# STM32F373C8T6 register map
File version: 1.0
STM32F373C8T6,STM32F373CBT6,STM32F373CBT7,STM32F373CCT6,STM32F373CCT7,STM32F373R8T6,STM32F373RBT6,STM32F373RBT7,STM32F373RCT6,STM32F373V8H6,STM32F373V8T6,STM32F373VBH6,STM32F373VBH7,STM32F373VBT6,STM32F373VBT7,STM32F373VCH6,STM32F373VCH7,STM32F373VCT6,STM32F373VCT7,STM32F378CCT6,STM32F378RCT6,STM32F378RCY6,STM32F378VCH6,STM32F378VCT6
Registers are 32-bit, access not given, reset 0x0 unless marked. A register's access mark holds for its fields unless they carry their own. Offsets are from the block's base; lines under a group give offsets from that group; [hi:lo] are bit positions; {n}, {i} and the like mark numbered series; 'fields as' and 'values as' point back to an identical list; <NAME> marks a mode.

## Memory map
0x40000000 TIM2
0x40000400 TIM3
0x40000800 TIM4
0x40000C00 TIM5
0x40001000 TIM6
0x40001400 TIM7
0x40001800 TIM12
0x40001C00 TIM13
0x40002000 TIM14
0x40002800 RTC
0x40002C00 WWDG
0x40003000 IWDG
0x40003800 SPI2
0x40003C00 SPI3
0x40004400 USART2
0x40004800 USART3
0x40005400 I2C1
0x40005800 I2C2
0x40005C00 USBFS
0x40006000 USB
0x40006400 CAN
0x40007000 PWR
0x40007400 DAC1
0x40007800 CEC
0x40009800 DAC2
0x40009C00 TIM18
0x40010000 COMP
0x40010000 SYSCFG
0x40010400 EXTI
0x40012400 ADC
0x40013000 SPI1
0x40013800 USART1
0x40014000 TIM15
0x40014400 TIM16
0x40014800 TIM17
0x40015800 DBGMCU
0x40015C00 TIM19
0x40016000 SDADC1
0x40016400 SDADC2
0x40016800 SDADC3
0x40020000 DMA1
0x40020400 DMA2
0x40021000 RCC
0x40022000 FLASH
0x40023000 CRC
0x40024000 TSC
0x48000000 GPIOA
0x48000400 GPIOB
0x48000800 GPIOC
0x48000C00 GPIOD
0x48001000 GPIOE
0x48001400 GPIOF

## TIM2
Base 0x40000000
Same registers: TIM3 0x40000400, TIM4 0x40000800, TIM5 0x40000C00, TIM19 0x40015C00
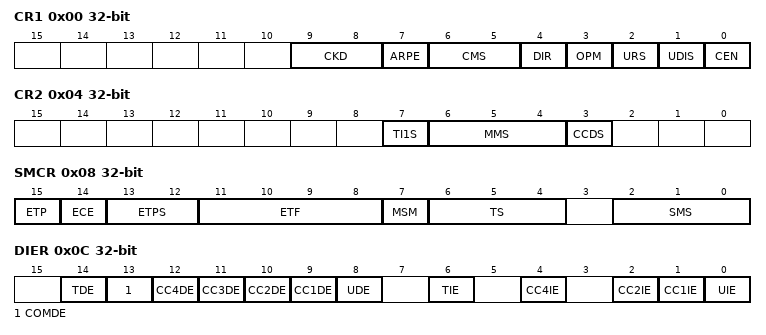
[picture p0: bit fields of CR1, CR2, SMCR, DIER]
0x00 CR1
  [9:8] CKD, [7] ARPE, [6:5] CMS, [4] DIR, [3] OPM, [2] URS, [1] UDIS, [0] CEN
0x04 CR2
  [7] TI1S, [6:4] MMS, [3] CCDS
0x08 SMCR
  [15] ETP, [14] ECE, [13:12] ETPS, [11:8] ETF, [7] MSM, [6:4] TS, [2:0] SMS
0x0C DIER
  [14] TDE, [13] COMDE, [n+8] CC{n}DE (n=1..4), [8] UDE, [6] TIE, [4] CC4IE, [2] CC2IE, [1] CC1IE, [0] UIE
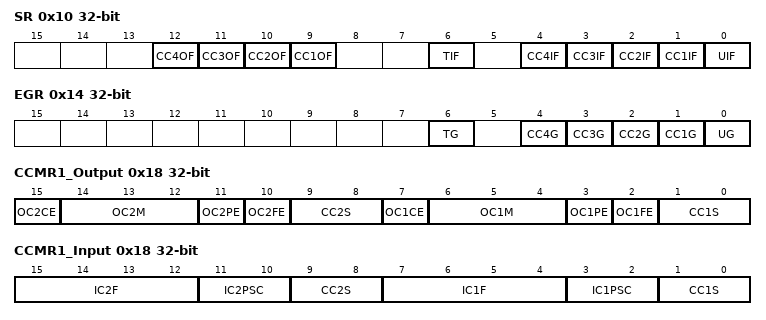
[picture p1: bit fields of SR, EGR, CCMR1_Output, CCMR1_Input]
0x10 SR
  [n+8] CC{n}OF (n=1..4), [6] TIF, [n] CC{n}IF (n=1..4), [0] UIF
0x14 EGR
  [6] TG, [n] CC{n}G (n=1..4), [0] UG
0x18 CCMR1_Output
  [15] OC2CE, [14:12] OC2M, [11] OC2PE, [10] OC2FE, [9:8] CC2S, [7] OC1CE, [6:4] OC1M, [3] OC1PE, [2] OC1FE, [1:0] CC1S
0x18 CCMR1_Input
  [15:12] IC2F, [11:10] IC2PSC, [9:8] CC2S, [7:4] IC1F, [3:2] IC1PSC, [1:0] CC1S
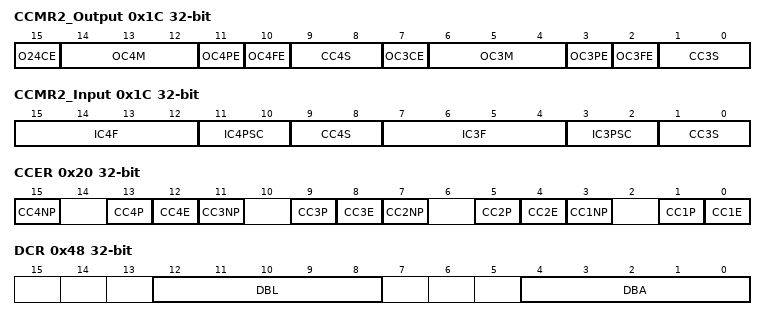
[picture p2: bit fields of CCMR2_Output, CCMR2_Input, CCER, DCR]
0x1C CCMR2_Output
  [15] O24CE, [14:12] OC4M, [11] OC4PE, [10] OC4FE, [9:8] CC4S, [7] OC3CE, [6:4] OC3M, [3] OC3PE, [2] OC3FE, [1:0] CC3S
0x1C CCMR2_Input
  [15:12] IC4F, [11:10] IC4PSC, [9:8] CC4S, [7:4] IC3F, [3:2] IC3PSC, [1:0] CC3S
0x20 CCER
  [4n-1] CC{n}NP (n=1..4), [4n-3] CC{n}P (n=1..4), [4n-4] CC{n}E (n=1..4)
0x24 CNT
0x28 PSC
  [15:0] PSC
0x2C ARR
{0x30+4i} CCR{i} (i=1..4)
0x48 DCR
  [12:8] DBL, [4:0] DBA
0x4C DMAR
  [15:0] DMAB

## TIM6
Base 0x40001000
Same registers: TIM7 0x40001400, TIM18 0x40009C00
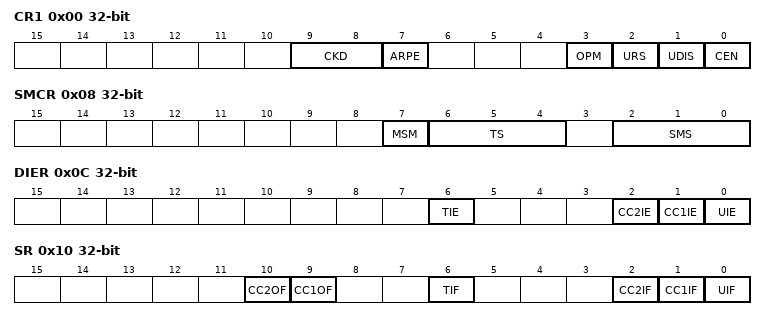
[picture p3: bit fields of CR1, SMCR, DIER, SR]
0x00 CR1
0x04 CR2
0x0C DIER
0x10 SR
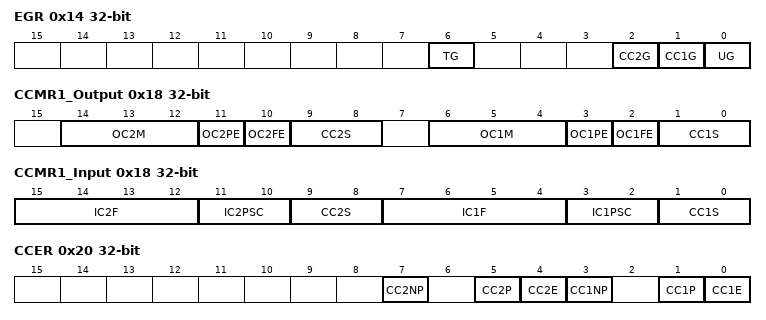
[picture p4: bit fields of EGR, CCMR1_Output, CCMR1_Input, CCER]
0x14 EGR
0x24 CNT
0x28 PSC
0x2C ARR

## TIM12
Base 0x40001800
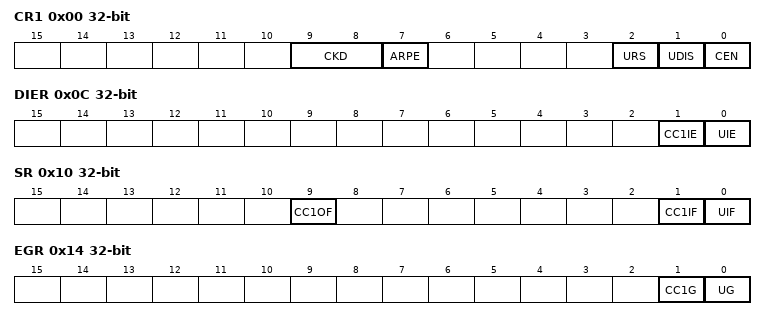
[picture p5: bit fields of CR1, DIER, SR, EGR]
0x00 CR1
  [9:8] CKD, [7] ARPE, [3] OPM, [2] URS, [1] UDIS, [0] CEN
0x04 CR2
  [6:4] MMS
0x08 SMCR
  [7] MSM, [6:4] TS, [2:0] SMS
0x0C DIER
  [6] TIE, [2] CC2IE, [1] CC1IE, [0] UIE
0x10 SR
  [10] CC2OF, [9] CC1OF, [6] TIF, [2] CC2IF, [1] CC1IF, [0] UIF
0x14 EGR
  [6] TG, [2] CC2G, [1] CC1G, [0] UG
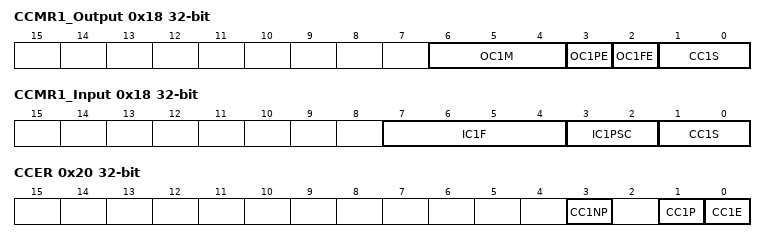
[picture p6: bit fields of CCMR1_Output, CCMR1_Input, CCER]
0x18 CCMR1_Output
  [14:12] OC2M, [11] OC2PE, [10] OC2FE, [9:8] CC2S, [6:4] OC1M, [3] OC1PE, [2] OC1FE, [1:0] CC1S
0x18 CCMR1_Input
  [15:12] IC2F, [11:10] IC2PSC, [9:8] CC2S, [7:4] IC1F, [3:2] IC1PSC, [1:0] CC1S
0x20 CCER
  [7] CC2NP, [5] CC2P, [4] CC2E, [3] CC1NP, [1] CC1P, [0] CC1E
0x24 CNT
  [15:0] CNT
0x28 PSC
  [15:0] PSC
0x2C ARR
  [15:0] ARR
0x34 CCR1
  [15:0] CCR1
0x38 CCR2
  [15:0] CCR2

## TIM13
Base 0x40001C00
0x00 CR1
  [9:8] CKD, [7] ARPE, [2] URS, [1] UDIS, [0] CEN
0x08 SMCR
0x0C DIER
  [1] CC1IE, [0] UIE
0x10 SR
  [9] CC1OF, [1] CC1IF, [0] UIF
0x14 EGR
  [1] CC1G, [0] UG
0x18 CCMR1_Output
  [6:4] OC1M, [3] OC1PE, [2] OC1FE, [1:0] CC1S
0x18 CCMR1_Input
  [7:4] IC1F, [3:2] IC1PSC, [1:0] CC1S
0x20 CCER
  [3] CC1NP, [1] CC1P, [0] CC1E
0x24 CNT
  [15:0] CNT
0x28 PSC
  [15:0] PSC
0x2C ARR
  [15:0] ARR
0x34 CCR1
  [15:0] CCR1

## TIM14
Base 0x40002000
Registers as TIM13; these are added or differ:
0x50 OR
  [1:0] TI1_RMP
